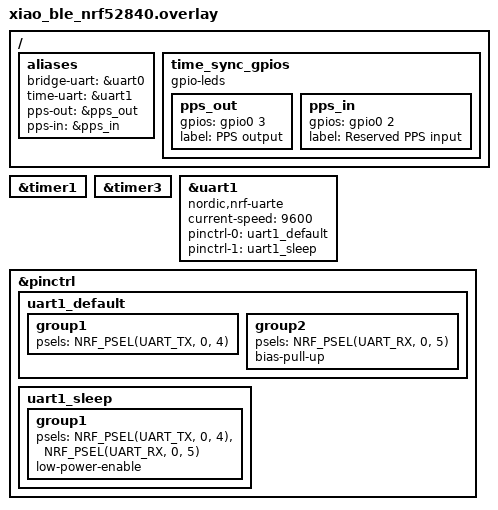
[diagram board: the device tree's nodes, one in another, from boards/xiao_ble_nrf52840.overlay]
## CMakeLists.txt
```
cmake_minimum_required(VERSION 3.20.0)

find_package(Zephyr REQUIRED HINTS $ENV{ZEPHYR_BASE})
project(xiao_nrf52840_plus_time_sync)

# Fail during configure instead of waiting for the firmware compiler/runtime to
# discover a malformed group key.  Kconfig exports string symbols as CMake
# variables after find_package(Zephyr).
if(DEFINED CONFIG_RADIO_BRIDGE_GROUP_KEY)
	string(LENGTH "${CONFIG_RADIO_BRIDGE_GROUP_KEY}" RB_GROUP_KEY_HEX_LENGTH)
	if(NOT RB_GROUP_KEY_HEX_LENGTH EQUAL 32 OR
	   NOT CONFIG_RADIO_BRIDGE_GROUP_KEY MATCHES "^[0-9A-Fa-f]+$")
		message(FATAL_ERROR
			"CONFIG_RADIO_BRIDGE_GROUP_KEY must contain exactly 32 hexadecimal characters")
	endif()
endif()

target_include_directories(app PRIVATE
	src/app
	src/config
	src/bridge
	src/radio
	src/time
	src/validation
)

target_sources(app PRIVATE
	src/config/bridge_config.c
	src/config/param_config.c
	src/config/param_shell.c
	src/bridge/byte_ring.c
	src/bridge/record_queue.c
	src/bridge/link_protocol.c
	src/bridge/fixed_peer_table.c
	src/bridge/link_scheduler_core.c
	src/bridge/uart_bridge.c
	src/bridge/uart_rx_recovery.c
	src/bridge/bridge_runtime.c
	src/radio/radio_address.c
	src/radio/radio_address_crypto.c
	src/radio/radio_transport_policy.c
	src/radio/radio_transport.c
	src/time/wireless_time_sync.c
	src/time/sync_tracker.c
	src/time/sync_filter.c
	src/time/time_sync_math.c
	src/time/timebase.c
	src/time/pps_output.c
	src/time/pps_input.c
	src/time/time_uart.c
	src/time/nmea_parser.c
	src/time/utc_clock.c
	src/time/time_sync_shell.c
	src/app/status.c
	src/app/heartbeat_led.c
	src/app/boot_recovery.c
	src/app/main.c
)

target_sources_ifdef(CONFIG_RADIO_BRIDGE_VALIDATION_CDC app PRIVATE
	src/validation/bridge_validation.c
	src/validation/bridge_validation_shell.c
	src/validation/boot_validation_shell.c
)

set(APP_GIT_VERSION "unknown")
find_package(Git QUIET)
if(Git_FOUND)
	execute_process(
		COMMAND ${GIT_EXECUTABLE} rev-parse --short=12 HEAD
		WORKING_DIRECTORY ${CMAKE_CURRENT_SOURCE_DIR}
		OUTPUT_VARIABLE APP_GIT_SHA
		OUTPUT_STRIP_TRAILING_WHITESPACE
		ERROR_QUIET
	)
	execute_process(
		COMMAND ${GIT_EXECUTABLE} diff --quiet HEAD --
		WORKING_DIRECTORY ${CMAKE_CURRENT_SOURCE_DIR}
		RESULT_VARIABLE APP_GIT_DIRTY_RESULT
		ERROR_QUIET
	)
	if(APP_GIT_SHA)
		set(APP_GIT_VERSION "${APP_GIT_SHA}")
		if(APP_GIT_DIRTY_RESULT EQUAL 1)
			set(APP_GIT_VERSION "${APP_GIT_VERSION}-dirty")
		endif()
	endif()
endif()

target_compile_definitions(app PRIVATE
	APP_GIT_VERSION="${APP_GIT_VERSION}"
	APP_LOG_FORMAT_VERSION=2
)
```

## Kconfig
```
source "Kconfig.zephyr"

menu "Star radio UART bridge"

config RADIO_BRIDGE_GROUP_ID
	int "Group identifier"
	default 1
	range 1 4294967294

config RADIO_BRIDGE_GROUP_KEY
	string "Group AES-128 key (32 hexadecimal characters)"
	default "00112233445566778899aabbccddeeff"

config RADIO_BRIDGE_UART_BAUDRATE
	int "Data UART baud rate"
	default 921600
	range 1200 3000000

config TIME_UART_BAUDRATE
	int "External time UART baud rate"
	default 9600
	range 1200 115200

config RADIO_BRIDGE_UART_RING_SIZE
	int "Bytes in each data UART ring"
	default 16384
	range 16384 32768

config RADIO_BRIDGE_AGGREGATION_TIMEOUT_US
	int "Partial radio payload aggregation timeout"
	default 1000
	range 100 10000

config RADIO_BRIDGE_SYNC_INTERVAL_US
	int "Wireless synchronization interval"
	default 100000
	range 10000 1000000

config RADIO_BRIDGE_LEASE_TIMEOUT_US
	int "Lease timeout without a valid poll"
	default 100000
	range 10000 1000000

config RADIO_BRIDGE_IDLE_POLL_MAX_US
	int "Maximum idle poll interval"
	default 5000
	range 1000 5000

config TIME_SYNC_PPS_WIDTH_US
	int "PPS pulse width"
	default 100000
	range 10 500000

config TIME_SYNC_RADIO_DELAY_US
	int "Calibrated slave radio delay"
	default 0
	range 0 1000

config TIME_SYNC_STATUS_INTERVAL_MS
	int "Status log interval"
	default 10000
	range 1000 60000

config TIME_SYNC_LED_HEARTBEAT
	bool "Blink board LED"
	default y

config TIME_SYNC_LED_HEARTBEAT_PERIOD_MS
	int "LED period"
	default 1000
	range 100 10000
	depends on TIME_SYNC_LED_HEARTBEAT

config RADIO_BRIDGE_TEST_LOSS_INJECTION
	bool "Enable radio packet loss injection for testing"
	default n
	help
	  When enabled, selected frame types can be dropped before transmission
	  or before queueing received frames.  Never enable in production role
	  configs (master.conf / slave.conf).

config RADIO_BRIDGE_VALIDATION_CDC
	bool "Enable CDC bridge payload validation commands"
	default n
	depends on SHELL
	help
	  Adds validation-only pattern injection and verification at the physical
	  UART/scheduler boundary. Keep disabled in production firmware.

endmenu
```

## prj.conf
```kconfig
CONFIG_GPIO=y
CONFIG_SERIAL=y
CONFIG_UART_ASYNC_API=y
CONFIG_ESB=y
CONFIG_ESB_MAX_PAYLOAD_LENGTH=252
CONFIG_ESB_PIPE_COUNT=4
CONFIG_ESB_SYS_TIMER1=y
CONFIG_ESB_DYNAMIC_INTERRUPTS=y
CONFIG_MPSL_DYNAMIC_INTERRUPTS=y
CONFIG_CRYPTO=y
CONFIG_CRYPTO_NRF_ECB=y
CONFIG_ENTROPY_GENERATOR=y
CONFIG_HWINFO=y
CONFIG_CONSOLE=y
CONFIG_UART_CONSOLE=y
CONFIG_LOG=y
CONFIG_LOG_BUFFER_SIZE=4096
CONFIG_LOG_PROCESS_THREAD_STARTUP_DELAY_MS=100
CONFIG_NRFX_GPIOTE=y
CONFIG_CLOCK_CONTROL=y
CONFIG_MAIN_STACK_SIZE=4096
CONFIG_SYSTEM_WORKQUEUE_STACK_SIZE=4096

# Runtime role configuration with NVS persistence (see param_config.c)
CONFIG_SETTINGS=y
CONFIG_FLASH=y
CONFIG_FLASH_MAP=y
CONFIG_MPU_ALLOW_FLASH_WRITE=y
# Without this, the SETTINGS_BACKEND choice has no eligible backend and
# silently falls back to SETTINGS_NONE, so settings_save_one() always fails
# with -ENOENT and every param set is lost on reboot.
CONFIG_NVS=y

# CDC Shell for runtime role configuration
CONFIG_SHELL=y
CONFIG_SHELL_BACKEND_SERIAL=y
CONFIG_SHELL_CMD_BUFF_SIZE=128
CONFIG_SHELL_PRINTF_BUFF_SIZE=128

# Watchdog - 自动重启防止卡死 (30秒超时)
CONFIG_WATCHDOG=y

# The shell backend's interrupt-driven mode selects the global
# UART_INTERRUPT_DRIVEN option, which flips the per-instance default for
# EVERY nRF UARTE instance to interrupt-driven -- including physical uart0
# (the data bridge UART), even though the shell itself runs over the CDC ACM
# virtual console, not uart0. uart_bridge.c requires uart0's async API
# (uart_callback_set/uart_rx_enable/uart_tx); force it back explicitly.
CONFIG_UART_0_INTERRUPT_DRIVEN=n
CONFIG_UART_1_INTERRUPT_DRIVEN=n
# uart_bridge_init() calls uart_configure() at runtime to apply the
# baud/parity/stop-bit settings read from the param system. Without this,
# z_impl_uart_configure() short-circuits to -ENOTSUP before ever reaching
# the driver, regardless of UART_0_ASYNC.
CONFIG_UART_USE_RUNTIME_CONFIGURE=y

CONFIG_REBOOT=y
CONFIG_UART_LINE_CTRL=y
```

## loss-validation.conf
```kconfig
CONFIG_RADIO_BRIDGE_TEST_LOSS_INJECTION=y
```

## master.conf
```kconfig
CONFIG_TIME_SYNC_ROLE_MASTER=y
CONFIG_BT_CENTRAL=y
CONFIG_BT_OBSERVER=y
CONFIG_BT_PERIPHERAL=n
CONFIG_BT_GATT_CLIENT=y
CONFIG_BT_SCAN=y
CONFIG_TIME_SYNC_MASTER_BLE_AUTO_START=y
```

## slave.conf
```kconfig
CONFIG_TIME_SYNC_ROLE_SLAVE=y
CONFIG_TIME_SYNC_RADIO_DELAY_US=17
CONFIG_BT_PERIPHERAL=y
CONFIG_BT_BROADCASTER=y
CONFIG_BT_CENTRAL=n
CONFIG_BT_OBSERVER=n
```

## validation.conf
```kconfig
CONFIG_RADIO_BRIDGE_VALIDATION_CDC=y
```

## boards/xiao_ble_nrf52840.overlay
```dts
&timer1 {
	status = "okay";
};

&timer3 {
	status = "okay";
};

/ {
	aliases {
		bridge-uart = &uart0;
		time-uart = &uart1;
		pps-out = &pps_out;
		pps-in = &pps_in;
	};

	time_sync_gpios {
		compatible = "gpio-leds";

		pps_out: pps_out {
			gpios = <&gpio0 3 GPIO_ACTIVE_HIGH>;
			label = "PPS output";
		};

		pps_in: pps_in {
			gpios = <&gpio0 2 GPIO_ACTIVE_HIGH>;
			label = "Reserved PPS input";
		};
	};
};

&uart1 {
	compatible = "nordic,nrf-uarte";
	status = "okay";
	current-speed = <9600>;
	pinctrl-0 = <&uart1_default>;
	pinctrl-1 = <&uart1_sleep>;
	pinctrl-names = "default", "sleep";
};

&pinctrl {
	uart1_default: uart1_default {
		group1 {
			psels = <NRF_PSEL(UART_TX, 0, 4)>;
		};
		group2 {
			psels = <NRF_PSEL(UART_RX, 0, 5)>;
			bias-pull-up;
		};
	};

	uart1_sleep: uart1_sleep {
		group1 {
			psels = <NRF_PSEL(UART_TX, 0, 4)>,
				<NRF_PSEL(UART_RX, 0, 5)>;
			low-power-enable;
		};
	};
};
```

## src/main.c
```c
#include <zephyr/kernel.h>
#include <zephyr/logging/log.h>
#include <zephyr/drivers/watchdog.h>
#include <zephyr/drivers/uart.h>
#include <zephyr/settings/settings.h>
#include <zephyr/sys/iterable_sections.h>
#include <zephyr/sys/reboot.h>
#include <zephyr/usb/usbd.h>
#include <zephyr/usb/usbd_msg.h>

#include <hal/nrf_power.h>

#include "app_config.h"
#include "bridge_config.h"
#include "bridge_runtime.h"
#include "heartbeat_led.h"
#include "link_protocol.h"
#include "param_config.h"
#include "pps_output.h"
#include "radio_transport.h"
#include "status.h"
#include "timebase.h"

LOG_MODULE_REGISTER(star_radio_main, LOG_LEVEL_INF);

static const struct device *wdt_dev;
static int wdt_channel_id;

static int watchdog_init(void)
{
	int ret;
	struct wdt_timeout_cfg wdt_config = {
		.window.min = 0,
		.window.max = 30000, /* 30秒超时 */
		.callback = NULL,
		.flags = WDT_FLAG_RESET_SOC,
	};

	wdt_dev = DEVICE_DT_GET(DT_NODELABEL(wdt0));
	if (!device_is_ready(wdt_dev)) {
		LOG_ERR("Watchdog device not ready");
		return -ENODEV;
	}

	wdt_channel_id = wdt_install_timeout(wdt_dev, &wdt_config);
	if (wdt_channel_id < 0) {
		LOG_ERR("Failed to install watchdog timeout: %d", wdt_channel_id);
		return wdt_channel_id;
	}

	ret = wdt_setup(wdt_dev, WDT_OPT_PAUSE_HALTED_BY_DBG);
	if (ret != 0) {
		LOG_ERR("Failed to setup watchdog: %d", ret);
		return ret;
	}

	LOG_INF("Watchdog enabled: 30s timeout, auto-reset on hang");
	return 0;
}

#define DFU_MAGIC_UF2_RESET 0x57u
#define RB_RADIO_BOOT_GUARD_KEY "diag/boot_guard"
#define RB_RADIO_BOOT_GUARD_MAGIC 0x52424744u
#define RB_RADIO_BOOT_GUARD_CLEAR_DELAY_MS 10000

struct radio_boot_guard_load_context {
	uint32_t value;
	bool found;
	int error;
};

static int radio_boot_guard_load_cb(const char *key, size_t len,
				    settings_read_cb read_cb, void *cb_arg,
				    void *param)
{
	struct radio_boot_guard_load_context *context = param;
	ssize_t bytes_read;

	if (settings_name_next(key, NULL) != 0) {
		return 0;
	}
	context->found = true;
	if (len != sizeof(context->value)) {
		context->error = -EINVAL;
		return 1;
	}
	bytes_read = read_cb(cb_arg, &context->value, sizeof(context->value));
	if (bytes_read != sizeof(context->value)) {
		context->error = bytes_read < 0 ? (int)bytes_read : -EIO;
	}
	return 1;
}

static void usbd_line_coding_cb(struct usbd_context *const ctx,
					const struct usbd_msg *const msg)
{
	uint32_t rate = 0u;

	ARG_UNUSED(ctx);
	if (msg == NULL || msg->type != USBD_MSG_CDC_ACM_LINE_CODING ||
		uart_line_ctrl_get(msg->dev, UART_LINE_CTRL_BAUD_RATE, &rate) != 0 ||
		rate != 1200u) {
		return;
	}

	LOG_INF("1200-baud UF2 reset requested");
	nrf_power_gpregret_set(NRF_POWER, 0, DFU_MAGIC_UF2_RESET);
	sys_reboot(SYS_REBOOT_COLD);
}

static void register_usbd_callbacks(void)
{
	STRUCT_SECTION_FOREACH(usbd_context, usbd_ctx) {
		int ret = usbd_msg_register_cb(usbd_ctx, usbd_line_coding_cb);

		if (ret != 0) {
			LOG_WRN("USB callback registration failed: %d", ret);
		}
	}
}

int main(void)
{
	int ret;
	bool led_heartbeat;
	bool boot_guard_armed = false;
	bool retained_diag_valid;
	int64_t boot_guard_clear_at;
	uint32_t reset_reason = nrf_power_resetreas_get(NRF_POWER);
	struct radio_boot_guard_load_context boot_guard = {0};
	struct rb_radio_retained_diag retained_diag = {0};
	uint32_t role_id, uart_baud, group_id, pps_period_us, status_interval_ms;
	uint32_t pps_width_us, led_period_ms;

	ret = rb_param_config_init();
	if (ret != 0) {
		LOG_ERR("param config init failed: %d", ret);
		return 0;
	}
	ret = settings_load_subtree_direct(RB_RADIO_BOOT_GUARD_KEY,
					 radio_boot_guard_load_cb, &boot_guard);
	if (ret != 0 || boot_guard.error != 0 || boot_guard.found) {
		int load_error = boot_guard.error != 0 ? boot_guard.error : ret;

		retained_diag_valid = radio_transport_retained_diag_get(&retained_diag);
		if (boot_guard.found) {
			ret = settings_delete(RB_RADIO_BOOT_GUARD_KEY);
			if (ret != 0) {
				LOG_ERR("radio boot guard clear failed: %d", ret);
			}
		}
		radio_transport_retained_diag_clear();
		register_usbd_callbacks();
		for (;;) {
			uint8_t history_start;

			LOG_ERR("radio boot guard recovered: reset_reason=0x%08x "
				"load_error=%d guard=0x%08x retained=%u stage=0x%02x "
				"switch=%u current=%u target=%u active=%u result=%d "
				"action=%u event=%u length=%u radio_state=%u "
				"events_disabled=%u hfclkstat=0x%08x primask=%u ipsr=%u "
				"updates=%u",
				reset_reason, load_error, boot_guard.value,
				retained_diag_valid, retained_diag.stage,
				retained_diag.switch_index,
				retained_diag.current_profile,
				retained_diag.target_profile,
				retained_diag.esb_active, retained_diag.last_result,
				retained_diag.runtime_action,
				retained_diag.radio_event_id,
				retained_diag.payload_length,
				retained_diag.radio_state,
				retained_diag.events_disabled,
				retained_diag.hfclkstat, retained_diag.primask,
				retained_diag.ipsr, retained_diag.update_count);
			history_start = (retained_diag.history_next +
				RB_RADIO_RETAINED_HISTORY_SIZE - retained_diag.history_count) %
				RB_RADIO_RETAINED_HISTORY_SIZE;
			for (uint8_t i = 0u; i < retained_diag.history_count; i++) {
				const struct rb_radio_retained_diag_entry *entry =
					&retained_diag.history[(history_start + i) %
						RB_RADIO_RETAINED_HISTORY_SIZE];

				LOG_ERR("radio diag history: seq=%u cycle=%u stage=0x%02x "
					"result=%d action=%u event=%u length=%u state=%u "
					"current=%u target=%u active=%u primask=%u",
					entry->sequence, entry->cycle, entry->stage,
					entry->result, entry->runtime_action,
					entry->radio_event_id, entry->payload_length,
					entry->radio_state, entry->current_profile,
					entry->target_profile, entry->esb_active,
					entry->primask);
				k_sleep(K_MSEC(100));
			}
			k_sleep(K_SECONDS(1));
		}
	}
	ret = settings_save_one(RB_RADIO_BOOT_GUARD_KEY,
				&((uint32_t){RB_RADIO_BOOT_GUARD_MAGIC}),
				sizeof(uint32_t));
	if (ret != 0) {
		register_usbd_callbacks();
		for (;;) {
			LOG_ERR("radio boot guard arm failed: %d; radio disabled", ret);
			k_sleep(K_SECONDS(2));
		}
	}
	boot_guard_armed = true;
	boot_guard_clear_at = k_uptime_get() + RB_RADIO_BOOT_GUARD_CLEAR_DELAY_MS;

	ret = rb_param_get_uint32(RB_PARAM_ROLE_ID, &role_id);
	if (ret != 0) {
		LOG_ERR("failed to read role_id: %d", ret);
		return 0;
	}

	ret = rb_param_get_uint32(RB_PARAM_UART_BAUDRATE, &uart_baud);
	if (ret != 0) {
		LOG_ERR("failed to read uart_baudrate: %d", ret);
		return 0;
	}
	ret = rb_param_get_uint32(RB_PARAM_GROUP_ID, &group_id);
	if (ret != 0) {
		LOG_ERR("failed to read group_id: %d", ret);
		return 0;
	}

	ret = rb_param_get_uint32(RB_PARAM_PPS_PERIOD_US, &pps_period_us);
	if (ret != 0) {
		LOG_ERR("failed to read pps_period_us: %d", ret);
		return 0;
	}

	ret = rb_param_get_uint32(RB_PARAM_PPS_WIDTH_US, &pps_width_us);
	if (ret != 0) {
		LOG_ERR("failed to read pps_width_us: %d", ret);
		return 0;
	}

	ret = rb_param_get_uint32(RB_PARAM_STATUS_INTERVAL_MS, &status_interval_ms);
	if (ret != 0) {
		LOG_ERR("failed to read status_interval_ms: %d", ret);
		return 0;
	}

	ret = rb_param_get_bool(RB_PARAM_LED_HEARTBEAT, &led_heartbeat);
	if (ret != 0) {
		LOG_ERR("failed to read led_heartbeat: %d", ret);
		return 0;
	}

	ret = rb_param_get_uint32(RB_PARAM_LED_PERIOD_MS, &led_period_ms);
	if (ret != 0) {
		LOG_ERR("failed to read led_period_ms: %d", ret);
		return 0;
	}

	LOG_INF("=== XIAO nRF52840 Star Radio UART Bridge ===");
	LOG_INF("Role: %s (role_id=%u), UART: %u baud",
		role_id == 0u ? "MASTER" : "SLAVE", role_id, uart_baud);

	ret = watchdog_init();
	if (ret != 0) {
		LOG_WRN("Watchdog init failed: %d (continuing without watchdog)", ret);
	}
	register_usbd_callbacks();

	ret = timebase_init();
	if (ret != 0) {
		LOG_ERR("timebase init failed: %d", ret);
		return 0;
	}
	ret = pps_output_init((uint16_t)pps_width_us);
	if (ret != 0) {
		LOG_ERR("pps init failed: %d", ret);
		return 0;
	}
	if (led_heartbeat) {
		ret = heartbeat_led_start((uint16_t)led_period_ms);
		if (ret != 0) {
			LOG_WRN("heartbeat LED disabled: %d", ret);
		}
	}
	ret = pps_output_start_periodic(timebase_now_us() + 100000u, pps_period_us);
	if (ret != 0) {
		LOG_ERR("pps periodic start failed: %d", ret);
		return 0;
	}
	ret = bridge_runtime_init();
	if (ret != 0) {
		LOG_ERR("bridge init failed: %d", ret);
		return 0;
	}
	ret = bridge_runtime_start();
	if (ret != 0) {
		LOG_ERR("bridge start failed: %d", ret);
		return 0;
	}

	LOG_INF("star bridge: group=%u channel=%u frequency=%uMHz payload=%u",
		group_id,
		(unsigned)rb_channel_index(group_id),
		(unsigned)rb_channel_frequency_mhz(group_id),
		(unsigned)RB_ESB_MAX_PAYLOAD);
	for (;;) {
		status_log_bridge();
		if (boot_guard_armed && k_uptime_get() >= boot_guard_clear_at) {
			ret = settings_delete(RB_RADIO_BOOT_GUARD_KEY);
			if (ret == 0) {
				boot_guard_armed = false;
				LOG_INF("radio boot guard cleared after stable startup");
			} else {
				LOG_ERR("radio boot guard clear failed: %d", ret);
				boot_guard_clear_at = INT64_MAX;
			}
		}
		if (wdt_dev != NULL) {
			wdt_feed(wdt_dev, wdt_channel_id);
		}
		k_sleep(K_MSEC(status_interval_ms));
	}
}
```

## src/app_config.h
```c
#ifndef APP_CONFIG_H
#define APP_CONFIG_H

#include <zephyr/kernel.h>

#define TIME_SYNC_NETWORK_ID_VALUE CONFIG_TIME_SYNC_NETWORK_ID
#define TIME_SYNC_RF_CHANNEL_VALUE CONFIG_TIME_SYNC_RF_CHANNEL
#define TIME_SYNC_INTERVAL_US_VALUE CONFIG_TIME_SYNC_INTERVAL_US
#define TIME_SYNC_PPS_PERIOD_US_VALUE CONFIG_TIME_SYNC_PPS_PERIOD_US
#define TIME_SYNC_PPS_WIDTH_US_VALUE CONFIG_TIME_SYNC_PPS_WIDTH_US
#define TIME_SYNC_RADIO_DELAY_US_VALUE CONFIG_TIME_SYNC_RADIO_DELAY_US
#define TIME_SYNC_RADIO_TXEN_TO_ADDRESS_US_VALUE CONFIG_TIME_SYNC_RADIO_TXEN_TO_ADDRESS_US
#define TIME_SYNC_MASTER_TX_TIMESLOT_LENGTH_US_VALUE CONFIG_TIME_SYNC_MASTER_TX_TIMESLOT_LENGTH_US
#define TIME_SYNC_MASTER_TX_START_OFFSET_US_VALUE CONFIG_TIME_SYNC_MASTER_TX_START_OFFSET_US
#define TIME_SYNC_TIMESLOT_LENGTH_US_VALUE CONFIG_TIME_SYNC_TIMESLOT_LENGTH_US
#define TIME_SYNC_TIMESLOT_END_MARGIN_US_VALUE CONFIG_TIME_SYNC_TIMESLOT_END_MARGIN_US
#define TIME_SYNC_RX_START_OFFSET_US_VALUE CONFIG_TIME_SYNC_RX_START_OFFSET_US
#define TIME_SYNC_TIMESLOT_REQUEST_TIMEOUT_US_VALUE CONFIG_TIME_SYNC_TIMESLOT_REQUEST_TIMEOUT_US
#define TIME_SYNC_RX_ACQUIRE_WINDOW_US_VALUE CONFIG_TIME_SYNC_RX_ACQUIRE_WINDOW_US
#define TIME_SYNC_RX_ACQUIRE_PERIOD_US_VALUE CONFIG_TIME_SYNC_RX_ACQUIRE_PERIOD_US
#define TIME_SYNC_RX_LOCKED_PRE_MARGIN_US_VALUE CONFIG_TIME_SYNC_RX_LOCKED_PRE_MARGIN_US
#define TIME_SYNC_RX_LOCKED_POST_MARGIN_US_VALUE CONFIG_TIME_SYNC_RX_LOCKED_POST_MARGIN_US
#define TIME_SYNC_RX_RECOVERY_PRE_MARGIN_US_VALUE CONFIG_TIME_SYNC_RX_RECOVERY_PRE_MARGIN_US
#define TIME_SYNC_RX_RECOVERY_POST_MARGIN_US_VALUE CONFIG_TIME_SYNC_RX_RECOVERY_POST_MARGIN_US
#define TIME_SYNC_RX_WINDOW_GUARD_US_VALUE CONFIG_TIME_SYNC_RX_WINDOW_GUARD_US
#define TIME_SYNC_RX_MISSED_TO_ACQUIRE_VALUE CONFIG_TIME_SYNC_RX_MISSED_TO_ACQUIRE
#define TIME_SYNC_STATUS_INTERVAL_MS_VALUE CONFIG_TIME_SYNC_STATUS_INTERVAL_MS
#define TIME_SYNC_LED_HEARTBEAT_PERIOD_MS_VALUE CONFIG_TIME_SYNC_LED_HEARTBEAT_PERIOD_MS
#define TIME_SYNC_BLE_DEVICE_NAME_PREFIX_VALUE CONFIG_TIME_SYNC_BLE_DEVICE_NAME_PREFIX

#if defined(CONFIG_TIME_SYNC_ROLE_MASTER) && defined(CONFIG_TIME_SYNC_ROLE_SLAVE)
#error "Select only one time sync role"
#endif

#if !defined(CONFIG_TIME_SYNC_ROLE_MASTER) && !defined(CONFIG_TIME_SYNC_ROLE_SLAVE)
#error "Select a time sync role"
#endif

#endif
```

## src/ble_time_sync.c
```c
#include "ble_time_sync.h"

#include "app_config.h"
#include "ble_time_sync_client.h"
#include "ble_time_sync_service.h"
#include "ble_time_sync_uuids.h"

#include <errno.h>
#include <string.h>

#include <zephyr/bluetooth/bluetooth.h>
#include <zephyr/bluetooth/conn.h>
#include <zephyr/bluetooth/gap.h>
#include <zephyr/kernel.h>
#include <zephyr/logging/log.h>
#include <zephyr/sys/atomic.h>

LOG_MODULE_REGISTER(ble_time_sync, LOG_LEVEL_INF);

K_MSGQ_DEFINE(ble_cmd_msgq, sizeof(struct ble_time_sync_command), 4, 4);

static atomic_t connected_count;
static atomic_t initialized;
static atomic_t bt_ready;
static atomic_t started;
static atomic_t start_attempts;
static atomic_t last_error;

#if defined(CONFIG_TIME_SYNC_ROLE_SLAVE)
static atomic_t ble_advertising;

static const struct bt_data slave_ad[] = {
	BT_DATA_BYTES(BT_DATA_FLAGS,
		      (BT_LE_AD_GENERAL | BT_LE_AD_NO_BREDR)),
	BT_DATA_BYTES(BT_DATA_UUID128_ALL,
		      BT_UUID_TIME_SYNC_SERVICE_VAL),
};
static char slave_name[CONFIG_BT_DEVICE_NAME_MAX];
static struct bt_data slave_sd[] = {
	BT_DATA(BT_DATA_NAME_COMPLETE, slave_name, 0),
};
static const struct bt_le_adv_param slave_adv_param =
	BT_LE_ADV_PARAM_INIT(BT_LE_ADV_OPT_CONN, BT_GAP_ADV_FAST_INT_MIN_2,
			     BT_GAP_ADV_FAST_INT_MAX_2, NULL);

static int slave_advertising_start(void)
{
	int ret = bt_le_adv_start(&slave_adv_param, slave_ad,
				  ARRAY_SIZE(slave_ad), slave_sd,
				  ARRAY_SIZE(slave_sd));

	if (ret == 0 || ret == -EALREADY) {
		atomic_set(&ble_advertising, 1);
	} else {
		atomic_set(&last_error, ret);
	}

	return ret;
}

static void command_received(const char *cmd, size_t len)
{
	struct ble_time_sync_command queued = {0};
	size_t copy_len;

	if (cmd == NULL || len == 0u) {
		return;
	}

	copy_len = MIN(len, sizeof(queued.text) - 1u);
	memcpy(queued.text, cmd, copy_len);

	if (k_msgq_put(&ble_cmd_msgq, &queued, K_NO_WAIT) != 0) {
		LOG_WRN("BLE command queue full");
	}
}
#endif

static void connected_cb(struct bt_conn *conn, uint8_t err)
{
	ARG_UNUSED(conn);

	if (err != 0) {
		LOG_WRN("BLE connect failed: %u", err);
#if defined(CONFIG_TIME_SYNC_ROLE_SLAVE)
		if (atomic_get(&started) == 0) {
			return;
		}

		int ret = slave_advertising_start();

		if (ret != 0 && ret != -EALREADY) {
			LOG_WRN("BLE advertising restart failed: %d", ret);
		}
#endif
		return;
	}

	atomic_inc(&connected_count);
#if defined(CONFIG_TIME_SYNC_ROLE_SLAVE)
	atomic_set(&ble_advertising, 0);
#endif
	LOG_INF("BLE connected count=%u", (uint32_t)atomic_get(&connected_count));
}

static void disconnected_cb(struct bt_conn *conn, uint8_t reason)
{
	ARG_UNUSED(conn);

	if (atomic_get(&connected_count) > 0) {
		atomic_dec(&connected_count);
	}

	LOG_INF("BLE disconnected reason=%u count=%u", reason,
		(uint32_t)atomic_get(&connected_count));

#if defined(CONFIG_TIME_SYNC_ROLE_SLAVE)
	if (atomic_get(&started) == 0) {
		return;
	}

	int ret = slave_advertising_start();

	if (ret != 0 && ret != -EALREADY) {
		LOG_WRN("BLE advertising restart failed: %d", ret);
	}
#endif
}

BT_CONN_CB_DEFINE(conn_callbacks) = {
	.connected = connected_cb,
	.disconnected = disconnected_cb,
};

bool ble_time_sync_connected(void)
{
	return atomic_get(&connected_count) > 0;
}

uint8_t ble_time_sync_connection_count(void)
{
	return (uint8_t)atomic_get(&connected_count);
}

int ble_time_sync_get_command(struct ble_time_sync_command *cmd)
{
	if (cmd == NULL) {
		return -EINVAL;
	}

	return k_msgq_get(&ble_cmd_msgq, cmd, K_NO_WAIT);
}

int ble_time_sync_init(void)
{
	if (atomic_get(&initialized) != 0) {
		return 0;
	}

#if defined(CONFIG_TIME_SYNC_ROLE_SLAVE)
	snprintk(slave_name, sizeof(slave_name), "%s-SLAVE",
		 TIME_SYNC_BLE_DEVICE_NAME_PREFIX_VALUE);
	slave_sd[0].data_len = strlen(slave_name);

	int ret = ble_time_sync_service_init(command_received);
	if (ret != 0) {
		return ret;
	}
#endif

	atomic_set(&initialized, 1);
	return 0;
}

static int ble_time_sync_enable_stack(void)
{
	int ret;

	if (atomic_get(&bt_ready) != 0) {
		return 0;
	}

	ret = ble_time_sync_init();
	if (ret != 0) {
		return ret;
	}

	ret = bt_enable(NULL);
	if (ret != 0) {
		return ret;
	}

#if defined(CONFIG_TIME_SYNC_ROLE_SLAVE)
	(void)bt_set_name(slave_name);
#elif defined(CONFIG_TIME_SYNC_ROLE_MASTER)
	char name[CONFIG_BT_DEVICE_NAME_MAX];

	snprintk(name, sizeof(name), "%s-MASTER",
		 TIME_SYNC_BLE_DEVICE_NAME_PREFIX_VALUE);
	(void)bt_set_name(name);
#endif

	atomic_set(&bt_ready, 1);
	return 0;
}

int ble_time_sync_start(void)
{
	int ret;

	atomic_inc(&start_attempts);
	ret = ble_time_sync_enable_stack();
	if (ret != 0) {
		atomic_set(&last_error, ret);
		return ret;
	}

	if (atomic_cas(&started, 0, 1) == false) {
		return 0;
	}

#if defined(CONFIG_TIME_SYNC_ROLE_SLAVE)
	ret = slave_advertising_start();
	if (ret == 0 || ret == -EALREADY) {
		atomic_set(&last_error, 0);
		LOG_INF("BLE advertising as %s", slave_name);
		return 0;
	}
#elif defined(CONFIG_TIME_SYNC_ROLE_MASTER)
	ret = ble_time_sync_client_start();
	if (ret == 0) {
		atomic_set(&last_error, 0);
		LOG_INF("BLE central started");
		return 0;
	}
#else
	ret = -ENOTSUP;
#endif

	atomic_set(&started, 0);
	atomic_set(&last_error, ret);
	return ret;
}

bool ble_time_sync_started(void)
{
	return atomic_get(&started) != 0;
}

void ble_time_sync_get_snapshot(struct ble_time_sync_snapshot *snapshot)
{
	if (snapshot == NULL) {
		return;
	}

	snapshot->initialized = atomic_get(&initialized) != 0;
	snapshot->bt_ready = atomic_get(&bt_ready) != 0;
	snapshot->started = atomic_get(&started) != 0;
	snapshot->connected = ble_time_sync_connected();
	snapshot->connection_count = ble_time_sync_connection_count();
	snapshot->peer_count = 0u;
	snapshot->start_attempts = (uint32_t)atomic_get(&start_attempts);
	snapshot->last_error = (int)atomic_get(&last_error);

#if defined(CONFIG_TIME_SYNC_ROLE_MASTER)
	snapshot->scanning = ble_time_sync_client_scanning();
	snapshot->peer = ble_time_sync_client_has_peer();
	snapshot->notify_enabled = ble_time_sync_client_notify_subscribed();
	snapshot->peer_count = ble_time_sync_client_peer_count();
	struct ble_time_sync_client_scan_stats scan_stats;

	ble_time_sync_client_get_scan_stats(&scan_stats);
	snapshot->scan_seen = scan_stats.scan_seen;
	snapshot->scan_match = scan_stats.scan_match;
	snapshot->scan_reject_type = scan_stats.scan_reject_type;
	snapshot->scan_reject_filter = scan_stats.scan_reject_filter;
	snapshot->connect_attempts = scan_stats.connect_attempts;
	snapshot->connect_failures = scan_stats.connect_failures;
	snapshot->gatt_tx_found = scan_stats.gatt_tx_found;
	snapshot->gatt_tx_ccc_found = scan_stats.gatt_tx_ccc_found;
	snapshot->gatt_subscribe_attempts =
		scan_stats.gatt_subscribe_attempts;
	snapshot->gatt_subscribe_failures =
		scan_stats.gatt_subscribe_failures;
	snapshot->gatt_notify_subscribed =
		scan_stats.gatt_notify_subscribed;
	snapshot->gatt_rx_found = scan_stats.gatt_rx_found;
	snapshot->gatt_write_attempts = scan_stats.gatt_write_attempts;
	snapshot->gatt_write_failures = scan_stats.gatt_write_failures;
	snapshot->gatt_write_successes = scan_stats.gatt_write_successes;
	snapshot->gatt_write_completions =
		scan_stats.gatt_write_completions;
	snapshot->gatt_write_retries = scan_stats.gatt_write_retries;
	snapshot->gatt_write_inflight = scan_stats.gatt_write_inflight;
	snapshot->gatt_write_step = scan_stats.gatt_write_step;
	snapshot->gatt_last_write_error =
		scan_stats.gatt_last_write_error;
#else
	snapshot->scanning = false;
	snapshot->peer = false;
	snapshot->scan_seen = 0;
	snapshot->scan_match = 0;
	snapshot->scan_reject_type = 0;
	snapshot->scan_reject_filter = 0;
	snapshot->connect_attempts = 0;
	snapshot->connect_failures = 0;
	snapshot->gatt_tx_found = 0;
	snapshot->gatt_tx_ccc_found = 0;
	snapshot->gatt_subscribe_attempts = 0;
	snapshot->gatt_subscribe_failures = 0;
	snapshot->gatt_notify_subscribed = 0;
	snapshot->gatt_rx_found = 0;
	snapshot->gatt_write_attempts = 0;
	snapshot->gatt_write_failures = 0;
	snapshot->gatt_write_successes = 0;
	snapshot->gatt_write_completions = 0;
	snapshot->gatt_write_retries = 0;
	snapshot->gatt_write_inflight = 0;
	snapshot->gatt_write_step = 0;
	snapshot->gatt_last_write_error = 0;
#endif

#if defined(CONFIG_TIME_SYNC_ROLE_SLAVE)
	snapshot->advertising = atomic_get(&ble_advertising) != 0;
	snapshot->notify_enabled = ble_time_sync_service_notify_enabled();
	snapshot->peer_count = snapshot->connection_count;
#else
	snapshot->advertising = false;
#endif
}
```

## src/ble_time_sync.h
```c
#ifndef BLE_TIME_SYNC_H
#define BLE_TIME_SYNC_H

#include <stdbool.h>
#include <stdint.h>

struct ble_time_sync_command {
	char text[128];
};

struct ble_time_sync_snapshot {
	bool initialized;
	bool bt_ready;
	bool started;
	bool connected;
	bool scanning;
	bool advertising;
	bool peer;
	bool notify_enabled;
	uint8_t connection_count;
	uint8_t peer_count;
	uint32_t start_attempts;
	uint32_t scan_seen;
	uint32_t scan_match;
	uint32_t scan_reject_type;
	uint32_t scan_reject_filter;
	uint32_t connect_attempts;
	uint32_t connect_failures;
	uint32_t gatt_tx_found;
	uint32_t gatt_tx_ccc_found;
	uint32_t gatt_subscribe_attempts;
	uint32_t gatt_subscribe_failures;
	uint32_t gatt_notify_subscribed;
	uint32_t gatt_rx_found;
	uint32_t gatt_write_attempts;
	uint32_t gatt_write_failures;
	uint32_t gatt_write_successes;
	uint32_t gatt_write_completions;
	uint32_t gatt_write_retries;
	uint32_t gatt_write_inflight;
	uint32_t gatt_write_step;
	int gatt_last_write_error;
	int last_error;
};

int ble_time_sync_init(void);
int ble_time_sync_start(void);
bool ble_time_sync_started(void);
bool ble_time_sync_connected(void);
uint8_t ble_time_sync_connection_count(void);
void ble_time_sync_get_snapshot(struct ble_time_sync_snapshot *snapshot);
int ble_time_sync_get_command(struct ble_time_sync_command *cmd);

#endif
```

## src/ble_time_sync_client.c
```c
#include "ble_time_sync_client.h"

#include "app_config.h"
#include "ble_time_sync_uuids.h"

#include <errno.h>
#include <string.h>

#include <zephyr/bluetooth/bluetooth.h>
#include <zephyr/bluetooth/conn.h>
#include <zephyr/bluetooth/gatt.h>
#include <zephyr/bluetooth/hci.h>
#include <zephyr/kernel.h>
#include <zephyr/logging/log.h>
#include <zephyr/sys/atomic.h>

LOG_MODULE_REGISTER(ble_time_sync_client, LOG_LEVEL_INF);

#if defined(CONFIG_TIME_SYNC_ROLE_MASTER)
#define SLAVE_NAME_SUFFIX "-SLAVE"
#define GATT_WRITE_RETRY_DELAY_MS 100
#define GATT_WRITE_NEXT_DELAY_MS 10

enum gatt_config_step {
	GATT_CONFIG_IDLE,
	GATT_CONFIG_SET_GROUP,
	GATT_CONFIG_START_SYNC,
	GATT_CONFIG_HELLO,
	GATT_CONFIG_DONE,
};

struct peer_state {
	struct bt_conn *conn;
	struct bt_gatt_discover_params discover_params;
	struct bt_gatt_subscribe_params subscribe_params;
	uint16_t rx_handle;
	uint16_t tx_value_handle;
	atomic_t notify_subscribed;
	atomic_t configured;
	atomic_t write_inflight;
	enum gatt_config_step write_step;
	char write_text[96];
	bool in_use;
};

struct adv_match {
	char name[CONFIG_BT_DEVICE_NAME_MAX];
	bool service_uuid_matches;
};

static struct peer_state peers[CONFIG_BT_MAX_CONN];
static atomic_t connecting;
static atomic_t scan_running;
static atomic_t scan_seen;
static atomic_t scan_match;
static atomic_t scan_reject_type;
static atomic_t scan_reject_filter;
static atomic_t connect_attempts;
static atomic_t connect_failures;
static atomic_t gatt_tx_found;
static atomic_t gatt_tx_ccc_found;
static atomic_t gatt_subscribe_attempts;
static atomic_t gatt_subscribe_failures;
static atomic_t gatt_notify_subscribed;
static atomic_t gatt_rx_found;
static atomic_t gatt_write_attempts;
static atomic_t gatt_write_failures;
static atomic_t gatt_write_successes;
static atomic_t gatt_write_completions;
static atomic_t gatt_write_retries;
static atomic_t gatt_write_inflight;
static atomic_t gatt_write_step;
static atomic_t gatt_last_write_error;
static const uint8_t service_uuid_ad[] = { BT_UUID_TIME_SYNC_SERVICE_VAL };
static const struct bt_le_scan_param scan_param =
	BT_LE_SCAN_PARAM_INIT(BT_LE_SCAN_TYPE_ACTIVE, BT_LE_SCAN_OPT_NONE,
			      BT_GAP_SCAN_FAST_INTERVAL,
			      BT_GAP_SCAN_FAST_WINDOW);
static const struct bt_le_conn_param conn_param =
	BT_LE_CONN_PARAM_INIT(BT_GAP_MS_TO_CONN_INTERVAL(200),
			      BT_GAP_MS_TO_CONN_INTERVAL(250), 0,
			      BT_GAP_MS_TO_CONN_TIMEOUT(4000));

static void scan_start(void);
static void discover_tx(struct bt_conn *conn);
static void discover_rx_start(struct bt_conn *conn);
static void gatt_write_work_handler(struct k_work *work);

K_WORK_DELAYABLE_DEFINE(gatt_write_work, gatt_write_work_handler);

static struct peer_state *peer_for_conn(struct bt_conn *conn)
{
	for (size_t i = 0; i < ARRAY_SIZE(peers); i++) {
		if (peers[i].in_use && peers[i].conn == conn) {
			return &peers[i];
		}
	}

	return NULL;
}

static struct peer_state *peer_alloc(struct bt_conn *conn)
{
	for (size_t i = 0; i < ARRAY_SIZE(peers); i++) {
		if (!peers[i].in_use) {
			memset(&peers[i], 0, sizeof(peers[i]));
			peers[i].conn = bt_conn_ref(conn);
			peers[i].write_step = GATT_CONFIG_DONE;
			peers[i].in_use = true;
			return &peers[i];
		}
	}

	return NULL;
}

static void clear_write_inflight(struct peer_state *peer)
{
	if (peer == NULL ||
	    atomic_cas(&peer->write_inflight, 1, 0) == false) {
		return;
	}

	if (atomic_get(&gatt_write_inflight) > 0) {
		atomic_dec(&gatt_write_inflight);
	}
}

static void peer_release(struct peer_state *peer)
{
	if (peer == NULL) {
		return;
	}

	clear_write_inflight(peer);

	if (peer->conn != NULL) {
		bt_conn_unref(peer->conn);
	}

	memset(peer, 0, sizeof(*peer));
}

static struct peer_state *peer_pending_write(void)
{
	for (size_t i = 0; i < ARRAY_SIZE(peers); i++) {
		if (peers[i].in_use &&
		    peers[i].write_step != GATT_CONFIG_DONE) {
			return &peers[i];
		}
	}

	return NULL;
}

static bool write_error_is_retryable(int ret)
{
	return ret == -ENOMEM || ret == -EAGAIN || ret == -EBUSY;
}

static void schedule_gatt_write_retry(void)
{
	atomic_inc(&gatt_write_retries);
	(void)k_work_schedule(&gatt_write_work,
			      K_MSEC(GATT_WRITE_RETRY_DELAY_MS));
}

static void schedule_gatt_write_next(void)
{
	(void)k_work_schedule(&gatt_write_work,
			      K_MSEC(GATT_WRITE_NEXT_DELAY_MS));
}

static const char *write_step_text(struct peer_state *peer)
{
	if (peer == NULL) {
		return NULL;
	}

	switch (peer->write_step) {
	case GATT_CONFIG_SET_GROUP:
		snprintk(peer->write_text, sizeof(peer->write_text),
			 "SET_GROUP network=0x%08x channel=%u interval=%u",
			 TIME_SYNC_NETWORK_ID_VALUE,
			 TIME_SYNC_RF_CHANNEL_VALUE,
			 TIME_SYNC_INTERVAL_US_VALUE);
		return peer->write_text;
	case GATT_CONFIG_START_SYNC:
		return "START_SYNC";
	case GATT_CONFIG_HELLO:
		return "HELLO_FROM_MASTER hello world";
	case GATT_CONFIG_DONE:
	default:
		return NULL;
	}
}

static void gatt_write_complete(struct bt_conn *conn, void *user_data)
{
	struct peer_state *peer = user_data;

	if (peer == NULL || !peer->in_use || peer->conn != conn) {
		return;
	}

	clear_write_inflight(peer);
	atomic_inc(&gatt_write_completions);
	atomic_set(&gatt_last_write_error, 0);

	if (peer->write_step < GATT_CONFIG_DONE) {
		peer->write_step =
			(enum gatt_config_step)(peer->write_step + 1);
		atomic_set(&gatt_write_step, (atomic_val_t)peer->write_step);
	}

	if (peer->write_step == GATT_CONFIG_DONE) {
		LOG_INF("BLE group config and hello sent handle=%u",
			peer->rx_handle);
		return;
	}

	schedule_gatt_write_next();
}

static int write_rx_text(struct peer_state *peer, const char *text)
{
	int ret;

	if (peer == NULL || peer->conn == NULL || peer->rx_handle == 0u ||
	    text == NULL) {
		return -EINVAL;
	}

	atomic_inc(&gatt_write_attempts);
	atomic_set(&peer->write_inflight, 1);
	atomic_inc(&gatt_write_inflight);
	ret = bt_gatt_write_without_response_cb(peer->conn, peer->rx_handle,
						text, strlen(text), false,
						gatt_write_complete, peer);
	if (ret != 0) {
		clear_write_inflight(peer);
		atomic_inc(&gatt_write_failures);
		atomic_set(&gatt_last_write_error, ret);
		LOG_WRN("BLE write failed: %d step=%u text=%s", ret,
			(uint32_t)peer->write_step, text);
	} else {
		atomic_inc(&gatt_write_successes);
		LOG_INF("BLE write queued step=%u text=%s",
			(uint32_t)peer->write_step, text);
	}

	return ret;
}

static void gatt_write_work_handler(struct k_work *work)
{
	struct peer_state *peer;
	const char *text;
	int ret;

	ARG_UNUSED(work);

	peer = peer_pending_write();
	if (peer == NULL || peer->conn == NULL || peer->rx_handle == 0u ||
	    atomic_get(&peer->notify_subscribed) == 0 ||
	    peer->write_step == GATT_CONFIG_DONE ||
	    atomic_get(&peer->write_inflight) != 0) {
		return;
	}

	text = write_step_text(peer);
	if (text == NULL) {
		return;
	}

	atomic_set(&gatt_write_step, (atomic_val_t)peer->write_step);
	ret = write_rx_text(peer, text);
	if (ret != 0) {
		if (write_error_is_retryable(ret)) {
			schedule_gatt_write_retry();
		} else {
			atomic_clear_bit(&peer->configured, 0);
			LOG_WRN("BLE write stopped after non-retryable error: %d",
				ret);
		}
		return;
	}
}

static void write_group_config(struct peer_state *peer)
{
	if (peer == NULL || peer->conn == NULL || peer->rx_handle == 0u ||
	    atomic_get(&peer->notify_subscribed) == 0 ||
	    atomic_test_and_set_bit(&peer->configured, 0)) {
		return;
	}

	peer->write_step = GATT_CONFIG_SET_GROUP;
	atomic_set(&gatt_write_step, (atomic_val_t)peer->write_step);
	schedule_gatt_write_next();
}

static void subscribe_complete(struct bt_conn *conn, uint8_t err,
			       struct bt_gatt_subscribe_params *params)
{
	struct peer_state *peer = peer_for_conn(conn);

	ARG_UNUSED(params);

	if (peer == NULL) {
		return;
	}

	if (err != 0) {
		LOG_WRN("BLE notify subscribe failed att_err=%u", err);
		atomic_inc(&gatt_subscribe_failures);
		return;
	}

	atomic_set(&peer->notify_subscribed, 1);
	atomic_inc(&gatt_notify_subscribed);
	LOG_INF("BLE notify subscribe complete");
	discover_rx_start(conn);
}

static uint8_t notify_rx(struct bt_conn *conn,
			 struct bt_gatt_subscribe_params *params,
			 const void *data, uint16_t length)
{
	char msg[128];
	size_t copy_len;

	ARG_UNUSED(conn);
	ARG_UNUSED(params);

	if (data == NULL) {
		return BT_GATT_ITER_STOP;
	}

	copy_len = MIN((size_t)length, sizeof(msg) - 1u);
	memcpy(msg, data, copy_len);
	msg[copy_len] = '\0';
	LOG_INF("BLE notify: %s", msg);

	return BT_GATT_ITER_CONTINUE;
}

static uint8_t discover_tx_ccc(struct bt_conn *conn,
			       const struct bt_gatt_attr *attr,
			       struct bt_gatt_discover_params *params)
{
	struct peer_state *peer = peer_for_conn(conn);
	int ret;

	if (peer == NULL) {
		return BT_GATT_ITER_STOP;
	}

	if (attr == NULL) {
		memset(params, 0, sizeof(*params));
		LOG_WRN("BLE TX CCC not found");
		return BT_GATT_ITER_STOP;
	}

	atomic_inc(&gatt_tx_ccc_found);
	memset(params, 0, sizeof(*params));
	peer->subscribe_params.notify = notify_rx;
	peer->subscribe_params.subscribe = subscribe_complete;
	peer->subscribe_params.value = BT_GATT_CCC_NOTIFY;
	peer->subscribe_params.value_handle = peer->tx_value_handle;
	peer->subscribe_params.ccc_handle = attr->handle;

	atomic_inc(&gatt_subscribe_attempts);
	ret = bt_gatt_subscribe(conn, &peer->subscribe_params);
	if (ret != 0 && ret != -EALREADY) {
		atomic_inc(&gatt_subscribe_failures);
		LOG_WRN("BLE notify subscribe failed: %d", ret);
	} else {
		LOG_INF("BLE TX notify subscribe queued");
	}

	return BT_GATT_ITER_STOP;
}

static uint8_t discover_tx_char(struct bt_conn *conn,
				const struct bt_gatt_attr *attr,
				struct bt_gatt_discover_params *params)
{
	struct peer_state *peer = peer_for_conn(conn);
	int ret;

	if (peer == NULL) {
		return BT_GATT_ITER_STOP;
	}

	if (attr == NULL) {
		memset(params, 0, sizeof(*params));
		LOG_WRN("BLE TX characteristic not found");
		return BT_GATT_ITER_STOP;
	}

	atomic_inc(&gatt_tx_found);
	peer->tx_value_handle = bt_gatt_attr_value_handle(attr);
	memset(params, 0, sizeof(*params));

	peer->discover_params.uuid = BT_UUID_GATT_CCC;
	peer->discover_params.func = discover_tx_ccc;
	peer->discover_params.start_handle = peer->tx_value_handle + 1u;
	peer->discover_params.end_handle = BT_ATT_LAST_ATTRIBUTE_HANDLE;
	peer->discover_params.type = BT_GATT_DISCOVER_DESCRIPTOR;

	ret = bt_gatt_discover(conn, &peer->discover_params);
	if (ret != 0) {
		LOG_WRN("BLE TX CCC discover failed: %d", ret);
	}

	return BT_GATT_ITER_STOP;
}

static uint8_t discover_rx(struct bt_conn *conn, const struct bt_gatt_attr *attr,
			   struct bt_gatt_discover_params *params)
{
	struct peer_state *peer = peer_for_conn(conn);

	if (peer == NULL) {
		return BT_GATT_ITER_STOP;
	}

	if (attr == NULL) {
		memset(params, 0, sizeof(*params));
		LOG_WRN("BLE RX characteristic not found");
		return BT_GATT_ITER_STOP;
	}

	atomic_inc(&gatt_rx_found);
	peer->rx_handle = bt_gatt_attr_value_handle(attr);
	memset(params, 0, sizeof(*params));
	LOG_INF("BLE RX characteristic handle=%u", peer->rx_handle);
	write_group_config(peer);

	return BT_GATT_ITER_STOP;
}

static void discover_rx_start(struct bt_conn *conn)
{
	struct peer_state *peer = peer_for_conn(conn);
	int ret;

	if (peer == NULL) {
		return;
	}

	peer->discover_params.uuid = &bt_uuid_time_sync_rx.uuid;
	peer->discover_params.func = discover_rx;
	peer->discover_params.start_handle = BT_ATT_FIRST_ATTRIBUTE_HANDLE;
	peer->discover_params.end_handle = BT_ATT_LAST_ATTRIBUTE_HANDLE;
	peer->discover_params.type = BT_GATT_DISCOVER_CHARACTERISTIC;

	ret = bt_gatt_discover(conn, &peer->discover_params);
	if (ret != 0) {
		LOG_WRN("BLE RX discover failed: %d", ret);
	}
}

static void discover_tx(struct bt_conn *conn)
{
	struct peer_state *peer = peer_for_conn(conn);
	int ret;

	if (peer == NULL) {
		return;
	}

	peer->discover_params.uuid = &bt_uuid_time_sync_tx.uuid;
	peer->discover_params.func = discover_tx_char;
	peer->discover_params.start_handle = BT_ATT_FIRST_ATTRIBUTE_HANDLE;
	peer->discover_params.end_handle = BT_ATT_LAST_ATTRIBUTE_HANDLE;
	peer->discover_params.type = BT_GATT_DISCOVER_CHARACTERISTIC;

	ret = bt_gatt_discover(conn, &peer->discover_params);
	if (ret != 0) {
		LOG_WRN("BLE TX discover failed: %d", ret);
	}
}

static bool parse_ad_cb(struct bt_data *data, void *user_data)
{
	struct adv_match *match = user_data;
	size_t len;

	if (data->type == BT_DATA_NAME_SHORTENED ||
	    data->type == BT_DATA_NAME_COMPLETE) {
		len = MIN((size_t)data->data_len,
			  (size_t)sizeof(match->name) - 1u);
		memcpy(match->name, data->data, len);
		match->name[len] = '\0';
		return true;
	}

	if (data->type == BT_DATA_UUID128_SOME ||
	    data->type == BT_DATA_UUID128_ALL) {
		for (uint8_t pos = 0;
		     pos + sizeof(service_uuid_ad) <= data->data_len;
		     pos += sizeof(service_uuid_ad)) {
			if (memcmp(&data->data[pos], service_uuid_ad,
				   sizeof(service_uuid_ad)) == 0) {
				match->service_uuid_matches = true;
				return true;
			}
		}
	}

	return true;
}

static bool name_matches_slave(const char *name)
{
	char expected[CONFIG_BT_DEVICE_NAME_MAX];

	snprintk(expected, sizeof(expected), "%s%s",
		 TIME_SYNC_BLE_DEVICE_NAME_PREFIX_VALUE, SLAVE_NAME_SUFFIX);

	return strcmp(name, expected) == 0;
}

static void device_found(const bt_addr_le_t *addr, int8_t rssi, uint8_t type,
			 struct net_buf_simple *ad)
{
	struct adv_match match = {0};
	char addr_str[BT_ADDR_LE_STR_LEN];
	struct bt_conn *conn = NULL;
	int ret;

	if (atomic_get(&connecting) != 0) {
		return;
	}

	atomic_inc(&scan_seen);

	if (type != BT_GAP_ADV_TYPE_ADV_IND &&
	    type != BT_GAP_ADV_TYPE_ADV_DIRECT_IND) {
		atomic_inc(&scan_reject_type);
		return;
	}

	bt_data_parse(ad, parse_ad_cb, &match);
	if (!match.service_uuid_matches && !name_matches_slave(match.name)) {
		atomic_inc(&scan_reject_filter);
		return;
	}

	atomic_inc(&scan_match);

	bt_addr_le_to_str(addr, addr_str, sizeof(addr_str));
	LOG_INF("BLE slave found %s rssi=%d name=%s", addr_str, rssi,
		match.name);

	ret = bt_le_scan_stop();
	if (ret != 0) {
		return;
	}

	atomic_set(&scan_running, 0);
	atomic_set(&connecting, 1);
	atomic_inc(&connect_attempts);

	ret = bt_conn_le_create(addr, BT_CONN_LE_CREATE_CONN,
				&conn_param, &conn);
	if (ret != 0) {
		LOG_WRN("BLE create connection failed: %d", ret);
		atomic_inc(&connect_failures);
		atomic_set(&connecting, 0);
		scan_start();
		return;
	}

	if (conn != NULL) {
		bt_conn_unref(conn);
	}
}

static void scan_start(void)
{
	int ret;

	if (atomic_get(&scan_running) != 0) {
		return;
	}

	ret = bt_le_scan_start(&scan_param, device_found);
	if (ret != 0) {
		LOG_WRN("BLE scan start failed: %d", ret);
		return;
	}

	atomic_set(&scan_running, 1);
	LOG_INF("BLE scan started");
}

static void connected_cb(struct bt_conn *conn, uint8_t err)
{
	struct peer_state *peer;

	atomic_set(&connecting, 0);

	if (err != 0) {
		LOG_WRN("BLE central connect failed: %u", err);
		atomic_inc(&connect_failures);
		scan_start();
		return;
	}

	peer = peer_alloc(conn);
	if (peer == NULL) {
		LOG_WRN("BLE peer table full");
		(void)bt_conn_disconnect(conn, BT_HCI_ERR_REMOTE_USER_TERM_CONN);
		scan_start();
		return;
	}

	LOG_INF("BLE central connected");
	discover_tx(conn);
}

static void disconnected_cb(struct bt_conn *conn, uint8_t reason)
{
	struct peer_state *peer = peer_for_conn(conn);

	ARG_UNUSED(reason);

	peer_release(peer);
	scan_start();
}

BT_CONN_CB_DEFINE(client_conn_callbacks) = {
	.connected = connected_cb,
	.disconnected = disconnected_cb,
};
#endif

int ble_time_sync_client_start(void)
{
#if defined(CONFIG_TIME_SYNC_ROLE_MASTER)
	scan_start();
	return 0;
#else
	return -ENOTSUP;
#endif
}

bool ble_time_sync_client_has_peer(void)
{
#if defined(CONFIG_TIME_SYNC_ROLE_MASTER)
	return ble_time_sync_client_peer_count() > 0u;
#endif

	return false;
}

uint8_t ble_time_sync_client_peer_count(void)
{
	uint8_t count = 0u;

#if defined(CONFIG_TIME_SYNC_ROLE_MASTER)
	for (size_t i = 0; i < ARRAY_SIZE(peers); i++) {
		if (peers[i].in_use) {
			count++;
		}
	}
#endif

	return count;
}

bool ble_time_sync_client_notify_subscribed(void)
{
#if defined(CONFIG_TIME_SYNC_ROLE_MASTER)
	for (size_t i = 0; i < ARRAY_SIZE(peers); i++) {
		if (peers[i].in_use &&
		    atomic_get(&peers[i].notify_subscribed) != 0) {
			return true;
		}
	}
#endif

	return false;
}

bool ble_time_sync_client_scanning(void)
{
#if defined(CONFIG_TIME_SYNC_ROLE_MASTER)
	return atomic_get(&scan_running) != 0;
#else
	return false;
#endif
}

void ble_time_sync_client_get_scan_stats(
	struct ble_time_sync_client_scan_stats *stats)
{
	if (stats == NULL) {
		return;
	}

#if defined(CONFIG_TIME_SYNC_ROLE_MASTER)
	stats->scan_seen = (uint32_t)atomic_get(&scan_seen);
	stats->scan_match = (uint32_t)atomic_get(&scan_match);
	stats->scan_reject_type = (uint32_t)atomic_get(&scan_reject_type);
	stats->scan_reject_filter =
		(uint32_t)atomic_get(&scan_reject_filter);
	stats->connect_attempts = (uint32_t)atomic_get(&connect_attempts);
	stats->connect_failures = (uint32_t)atomic_get(&connect_failures);
	stats->gatt_tx_found = (uint32_t)atomic_get(&gatt_tx_found);
	stats->gatt_tx_ccc_found = (uint32_t)atomic_get(&gatt_tx_ccc_found);
	stats->gatt_subscribe_attempts =
		(uint32_t)atomic_get(&gatt_subscribe_attempts);
	stats->gatt_subscribe_failures =
		(uint32_t)atomic_get(&gatt_subscribe_failures);
	stats->gatt_notify_subscribed =
		(uint32_t)atomic_get(&gatt_notify_subscribed);
	stats->gatt_rx_found = (uint32_t)atomic_get(&gatt_rx_found);
	stats->gatt_write_attempts =
		(uint32_t)atomic_get(&gatt_write_attempts);
	stats->gatt_write_failures =
		(uint32_t)atomic_get(&gatt_write_failures);
	stats->gatt_write_successes =
		(uint32_t)atomic_get(&gatt_write_successes);
	stats->gatt_write_completions =
		(uint32_t)atomic_get(&gatt_write_completions);
	stats->gatt_write_retries =
		(uint32_t)atomic_get(&gatt_write_retries);
	stats->gatt_write_inflight =
		(uint32_t)atomic_get(&gatt_write_inflight);
	stats->gatt_write_step =
		(uint32_t)atomic_get(&gatt_write_step);
	stats->gatt_last_write_error =
		(int)atomic_get(&gatt_last_write_error);
#else
	memset(stats, 0, sizeof(*stats));
#endif
}
```

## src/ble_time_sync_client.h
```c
#ifndef BLE_TIME_SYNC_CLIENT_H
#define BLE_TIME_SYNC_CLIENT_H

#include <stdbool.h>
#include <stdint.h>

struct ble_time_sync_client_scan_stats {
	uint32_t scan_seen;
	uint32_t scan_match;
	uint32_t scan_reject_type;
	uint32_t scan_reject_filter;
	uint32_t connect_attempts;
	uint32_t connect_failures;
	uint32_t gatt_tx_found;
	uint32_t gatt_tx_ccc_found;
	uint32_t gatt_subscribe_attempts;
	uint32_t gatt_subscribe_failures;
	uint32_t gatt_notify_subscribed;
	uint32_t gatt_rx_found;
	uint32_t gatt_write_attempts;
	uint32_t gatt_write_failures;
	uint32_t gatt_write_successes;
	uint32_t gatt_write_completions;
	uint32_t gatt_write_retries;
	uint32_t gatt_write_inflight;
	uint32_t gatt_write_step;
	int gatt_last_write_error;
};

int ble_time_sync_client_start(void);
bool ble_time_sync_client_has_peer(void);
bool ble_time_sync_client_scanning(void);
uint8_t ble_time_sync_client_peer_count(void);
bool ble_time_sync_client_notify_subscribed(void);
void ble_time_sync_client_get_scan_stats(
	struct ble_time_sync_client_scan_stats *stats);

#endif
```

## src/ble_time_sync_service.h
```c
#ifndef BLE_TIME_SYNC_SERVICE_H
#define BLE_TIME_SYNC_SERVICE_H

#include <stdbool.h>
#include <stddef.h>

typedef void (*ble_time_sync_command_handler_t)(const char *cmd, size_t len);

int ble_time_sync_service_init(ble_time_sync_command_handler_t handler);
int ble_time_sync_service_notify(const char *msg);
bool ble_time_sync_service_notify_enabled(void);
const char *ble_time_sync_service_status(void);

#endif
```

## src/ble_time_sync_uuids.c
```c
#include "ble_time_sync_uuids.h"

const struct bt_uuid_128 bt_uuid_time_sync_service =
	BT_UUID_INIT_128(BT_UUID_TIME_SYNC_SERVICE_VAL);
const struct bt_uuid_128 bt_uuid_time_sync_rx =
	BT_UUID_INIT_128(BT_UUID_TIME_SYNC_RX_VAL);
const struct bt_uuid_128 bt_uuid_time_sync_tx =
	BT_UUID_INIT_128(BT_UUID_TIME_SYNC_TX_VAL);
const struct bt_uuid_128 bt_uuid_time_sync_status =
	BT_UUID_INIT_128(BT_UUID_TIME_SYNC_STATUS_VAL);
```
